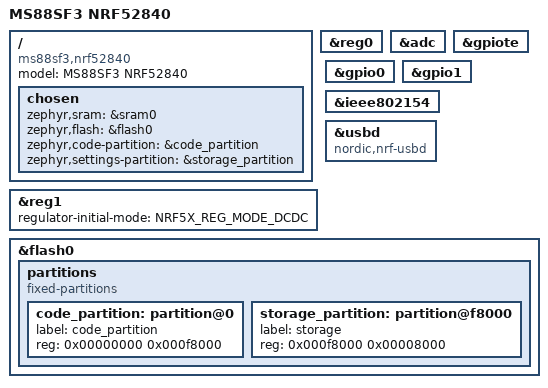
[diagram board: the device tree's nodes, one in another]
/*
 * Copyright (c) 2024 Marcus
 * SPDX-License-Identifier: MIT
 */

/dts-v1/;
#include <nordic/nrf52840_qiaa.dtsi>

/ {
	model = "MS88SF3 NRF52840";
	compatible = "ms88sf3,nrf52840";

	chosen {
		zephyr,sram = &sram0;
		zephyr,flash = &flash0;
		zephyr,code-partition = &code_partition;
		zephyr,settings-partition = &storage_partition; 
	};
};

&reg0 {
	status = "okay";
};

&reg1 {
	regulator-initial-mode = <NRF5X_REG_MODE_DCDC>;
};

&adc {
	status = "okay";
};

&gpiote {
	status = "okay";
};

&gpio0 {
	status = "okay";
};

&gpio1 {
	status = "okay";
};

&ieee802154 {
	status = "okay";
};

zephyr_udc0: &usbd {
	compatible = "nordic,nrf-usbd";
	status = "okay";
};

&flash0 {
	partitions {
		compatible = "fixed-partitions";
		#address-cells = <1>;
		#size-cells = <1>;

		/* Code partition - starts at 0x0 for SWD programming */
		code_partition: partition@0 {
			label = "code_partition";
			reg = <0x00000000 0x000f8000>;
		};

		/* Storage partition for settings (32KB at end) */
		storage_partition: partition@f8000 {
			label = "storage";
			reg = <0x000f8000 0x00008000>;
		};
	};
};
